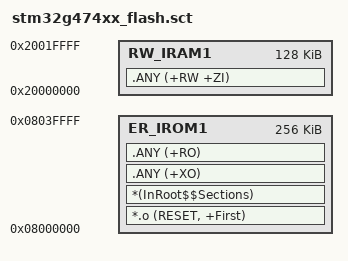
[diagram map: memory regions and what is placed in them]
LR_IROM1 0x8000000 0x00040000  {
  ER_IROM1 0x8000000 0x00040000  {
    *.o (RESET, +First)
    *(InRoot$$Sections)
    .ANY (+XO)
    .ANY (+RO)
  }
;***region***;
;***endregion***;
  RW_IRAM1 0x20000000 0x00020000  {
    .ANY (+RW +ZI)
  }
}
/*-Start of  regions- Auto-generated By STM32CubeMX-*/
